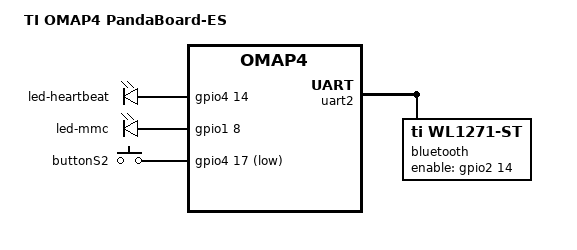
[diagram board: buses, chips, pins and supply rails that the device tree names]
/dts-v1/;
#include "omap4460.dtsi"
#include "omap4-panda-common.dtsi"
/ {
	model = "TI OMAP4 PandaBoard-ES";
	compatible = "ti,omap4-panda-es", "ti,omap4-panda", "ti,omap4460", "ti,omap4430", "ti,omap4";
};
&sound {
	ti,model = "PandaBoardES";
	ti,audio-routing =
		"Headset Stereophone", "HSOL",
		"Headset Stereophone", "HSOR",
		"Ext Spk", "HFL",
		"Ext Spk", "HFR",
		"Line Out", "AUXL",
		"Line Out", "AUXR",
		"AFML", "Line In",
		"AFMR", "Line In";
};
&dss_hdmi_pins {
	pinctrl-single,pins = <
		OMAP4_IOPAD(0x09a, PIN_INPUT | MUX_MODE0)		 
		OMAP4_IOPAD(0x09c, PIN_INPUT | MUX_MODE0)		 
		OMAP4_IOPAD(0x09e, PIN_INPUT | MUX_MODE0)		 
		>;
};
&omap4_pmx_core {
	led_gpio_pins: gpio-led-pmx-pins {
		pinctrl-single,pins = <
			OMAP4_IOPAD(0x0f6, PIN_OUTPUT | MUX_MODE3)	 
		>;
	};
	button_pins: button-pins {
		pinctrl-single,pins = <
			OMAP4_IOPAD(0x0fc, PIN_INPUT_PULLUP | MUX_MODE3)  
		>;
	};
	bt_pins: bt-pins {
		pinctrl-single,pins = <
			OMAP4_IOPAD(0x06c, PIN_OUTPUT | MUX_MODE3)		 
			OMAP4_IOPAD(0x072, PIN_OUTPUT_PULLUP | MUX_MODE3)	 
		>;
	};
	uart2_pins: uart2-pins {
		pinctrl-single,pins = <
			OMAP4_IOPAD(0x118, PIN_INPUT_PULLUP | MUX_MODE0)	 
			OMAP4_IOPAD(0x11a, PIN_OUTPUT | MUX_MODE0)		 
			OMAP4_IOPAD(0x11c, PIN_INPUT_PULLUP | MUX_MODE0)	 
			OMAP4_IOPAD(0x11e, PIN_OUTPUT | MUX_MODE0)		 
		>;
	};
};
&led_wkgpio_pins {
	pinctrl-single,pins = <
		OMAP4_IOPAD(0x05c, PIN_OUTPUT | MUX_MODE3)	 
	>;
};
&leds {
	pinctrl-0 = <
		&led_gpio_pins
		&led_wkgpio_pins
	>;
	led-heartbeat {
		gpios = <&gpio4 14 GPIO_ACTIVE_HIGH>;
	};
	led-mmc {
		gpios = <&gpio1 8 GPIO_ACTIVE_HIGH>;
	};
};
&gpio_keys {
	buttonS2 {
		gpios = <&gpio4 17 GPIO_ACTIVE_LOW>;  
	};
};
&gpio1_target {
	 ti,no-reset-on-init;
};
&wl12xx_gpio {
	pinctrl-single,pins = <
		OMAP4_IOPAD(0x066, PIN_OUTPUT | MUX_MODE3)		 
		OMAP4_IOPAD(0x070, PIN_OUTPUT_PULLUP | MUX_MODE3)	 
	>;
};
&uart2 {
	pinctrl-names = "default";
	pinctrl-0 = <&uart2_pins &bt_pins>;
	bluetooth: tiwi {
		compatible = "ti,wl1271-st";
		enable-gpios = <&gpio2 14 GPIO_ACTIVE_HIGH>;	 
	};
};
